# PRM_CEFUSE register map
Vendor: Texas Instruments
Peripheral module from a debugger description file (folder am437x).
Registers are 32-bit, access per field, no defined reset value unless marked. A register's access mark holds for its fields unless they carry their own. Offsets are as the file gives them; lines under a group give offsets from that group; [hi:lo] are bit positions; {n}, {i} and the like mark numbered series; 'fields as' and 'values as' point back to an identical list; <NAME> marks a mode.

## PRM_CEFUSE
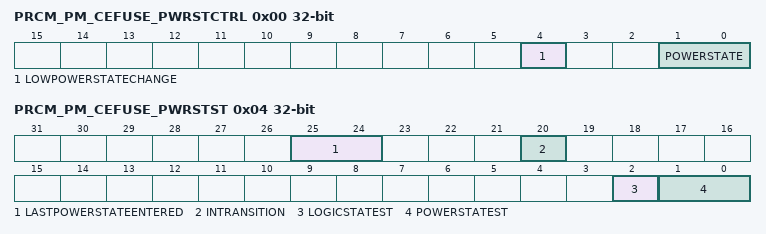
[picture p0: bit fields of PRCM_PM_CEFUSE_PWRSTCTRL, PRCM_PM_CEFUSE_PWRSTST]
0x00 PRCM_PM_CEFUSE_PWRSTCTRL — This register controls the CEFUSE power state to reach upon a domain sleep transition
  [4] LOWPOWERSTATECHANGE rw — Power state change request when domain has already performed a sleep transition. [[br]]Allows going into deeper low power state without waking up the power domain.
    1=en_2_0x1 (Request a low power state change. This bit is automatically cleared when the power state is effectively changed or when power state is ON.); 0=en_1_0x0 (Do not request a low power state change.)
  [1:0] POWERSTATE rw — Power state control
    3=en_4_0x3 (ON State); 2=en_3_0x2 (RESERVED); 1=en_2_0x1 (RESERVED); 0=en_1_0x0 (OFF state)
0x04 PRCM_PM_CEFUSE_PWRSTST — This register provides a status on the current CEFUSE power domain state. [warm reset insensitive]
  [25:24] LASTPOWERSTATEENTERED rw — Last low power state entered. [[br]]Set to 0x3 upon write of the same only. [[br]]This register is intended for debug purpose only.
    1=en_2_0x1 (Power domain was previously ON-ACTIVE); 0=en_1_0x0 (Power domain was previously OFF)
  [20] INTRANSITION ro — Domain transition status
    1=en_2_0x1 (Power domain transition is in progress.); 0=en_1_0x0 (No on-going transition on power domain)
  [2] LOGICSTATEST ro — Logic state status
    1=en_2_0x1 (Logic in domain is ON); 0=en_1_0x0 (Logic in domain is OFF)
  [1:0] POWERSTATEST ro — Current power state status
    3=en_2_0x3 (Power domain is ON-ACTIVE); 0=en_1_0x0 (Power domain is OFF)
0x24 PRCM_RM_CEFUSE_CONTEXT — This register contains dedicated CEFUSE module context statuses. [warm reset insensitive]
  [0] LOSTCONTEXT_DFF rw — Specify if DFF-based context has been lost due to a previous power transition or other reset source. [[br]](set upon assertion of CUST_EFUSE_RST signal)
    1=en_2_0x1 (Context has been lost); 0=en_1_0x0 (Context has been maintained)
